VERSION ""

NS_ :

BS_:

BU_: IMU ECU IRTS_FL ACQUISINATOR TLM IRTS_FL TLM IRTS_FL TLM IRTS_FL TLM IRTS_FR TLM IRTS_FR ACQUISINATOR IRTS_FR IMU ACQUISINATOR IRTS_FR TLM IRTS_RL ACQUISINATOR IRTS_RL TLM IRTS_RL TLM TLM IRTS_RL ACQUISINATOR IRTS_RR ACQUISINATOR IRTS_RR TLM IRTS_RR IRTS_RR TLM TLM TLM ECU ECU ECU ACQUISINATOR

BO_ 0 ACQUISINATOR_JMP_TO_BLT: 1 Vector__XXX
 SG_ acquisinatore_id : 0|8@1+ (1,0) [0|255] "" Vector__XXX

BO_ 1 ACQUISINATOR_FLASH_TX: 0 Vector__XXX

BO_ 2 ACQUISINATOR_FLASH_RX: 0 Vector__XXX

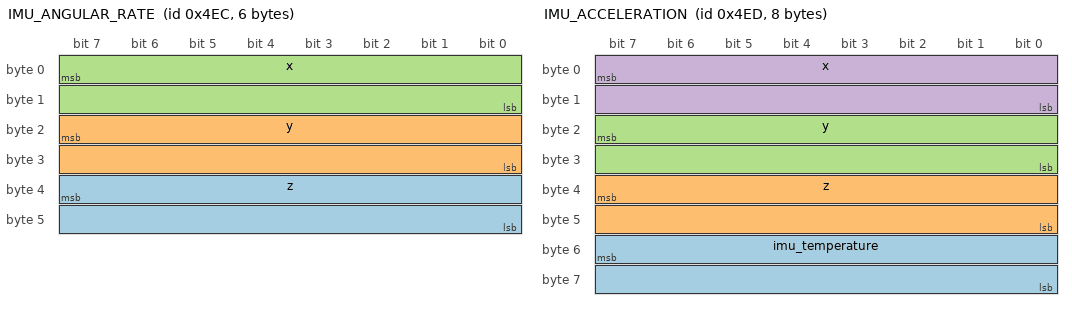
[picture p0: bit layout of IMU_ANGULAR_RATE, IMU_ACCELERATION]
BO_ 1260 IMU_ANGULAR_RATE: 6 Vector__XXX
 SG_ z : 39|16@0- (0.1,0) [0|245] "" Vector__XXX
 SG_ y : 23|16@0- (0.1,0) [0|245] "" Vector__XXX
 SG_ x : 7|16@0- (0.1,0) [0|245] "" Vector__XXX

BO_ 1261 IMU_ACCELERATION: 8 Vector__XXX
 SG_ imu_temperature : 55|16@0- (1,-32768) [-32768|32767] "" Vector__XXX
 SG_ z : 39|16@0- (0.01,0) [0|8] "" Vector__XXX
 SG_ y : 23|16@0- (0.01,0) [0|8] "" Vector__XXX
 SG_ x : 7|16@0- (0.01,0) [0|8] "" Vector__XXX

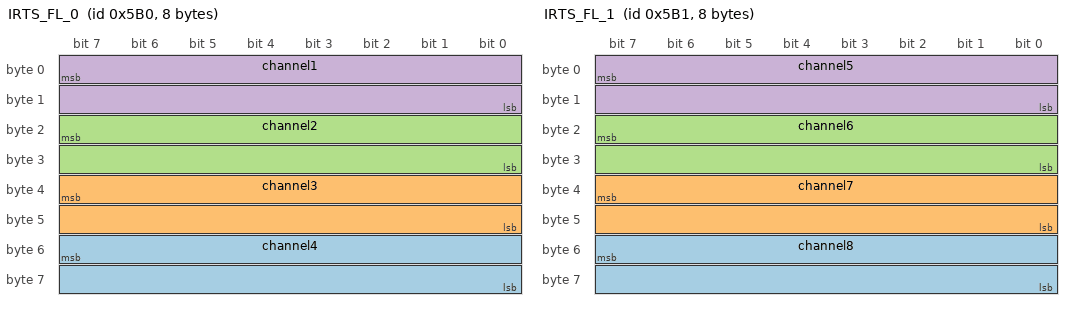
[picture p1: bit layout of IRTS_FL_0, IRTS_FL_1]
BO_ 1456 IRTS_FL_0: 8 Vector__XXX
 SG_ channel4 : 55|16@0+ (0.1,-100) [-100|0] "" Vector__XXX
 SG_ channel3 : 39|16@0+ (0.1,-100) [-100|0] "" Vector__XXX
 SG_ channel2 : 23|16@0+ (0.1,-100) [-100|0] "" Vector__XXX
 SG_ channel1 : 7|16@0+ (0.1,-100) [-100|0] "" Vector__XXX

BO_ 1457 IRTS_FL_1: 8 Vector__XXX
 SG_ channel8 : 55|16@0+ (0.1,-100) [-100|0] "" Vector__XXX
 SG_ channel7 : 39|16@0+ (0.1,-100) [-100|0] "" Vector__XXX
 SG_ channel6 : 23|16@0+ (0.1,-100) [-100|0] "" Vector__XXX
 SG_ channel5 : 7|16@0+ (0.1,-100) [-100|0] "" Vector__XXX

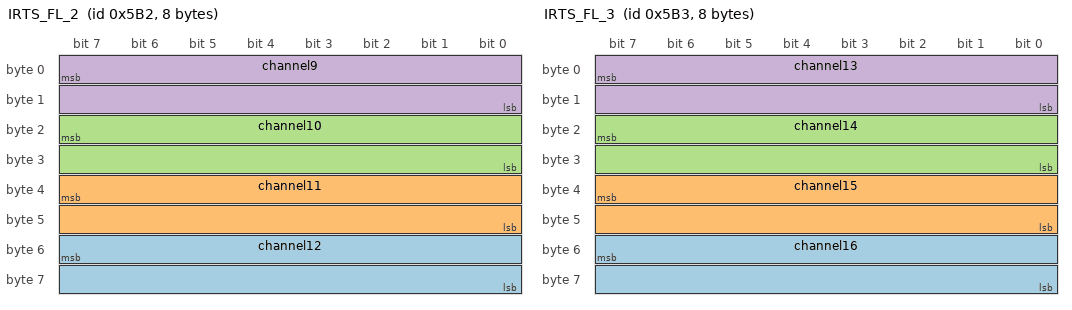
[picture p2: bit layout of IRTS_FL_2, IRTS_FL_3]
BO_ 1458 IRTS_FL_2: 8 Vector__XXX
 SG_ channel12 : 55|16@0+ (0.1,-100) [-100|0] "" Vector__XXX
 SG_ channel11 : 39|16@0+ (0.1,-100) [-100|0] "" Vector__XXX
 SG_ channel10 : 23|16@0+ (0.1,-100) [-100|0] "" Vector__XXX
 SG_ channel9 : 7|16@0+ (0.1,-100) [-100|0] "" Vector__XXX

BO_ 1459 IRTS_FL_3: 8 Vector__XXX
 SG_ channel16 : 55|16@0+ (0.1,-100) [-100|0] "" Vector__XXX
 SG_ channel15 : 39|16@0+ (0.1,-100) [-100|0] "" Vector__XXX
 SG_ channel14 : 23|16@0+ (0.1,-100) [-100|0] "" Vector__XXX
 SG_ channel13 : 7|16@0+ (0.1,-100) [-100|0] "" Vector__XXX

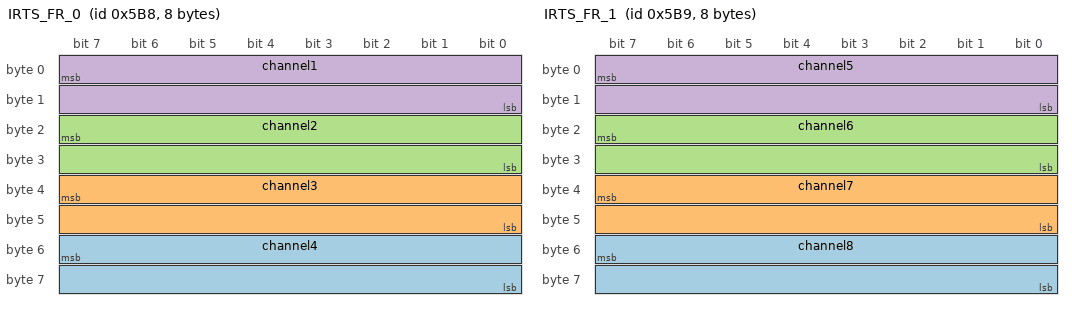
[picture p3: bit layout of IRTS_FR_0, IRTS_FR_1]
BO_ 1464 IRTS_FR_0: 8 Vector__XXX
 SG_ channel4 : 55|16@0+ (0.1,-100) [-100|0] "" Vector__XXX
 SG_ channel3 : 39|16@0+ (0.1,-100) [-100|0] "" Vector__XXX
 SG_ channel2 : 23|16@0+ (0.1,-100) [-100|0] "" Vector__XXX
 SG_ channel1 : 7|16@0+ (0.1,-100) [-100|0] "" Vector__XXX

BO_ 1465 IRTS_FR_1: 8 Vector__XXX
 SG_ channel8 : 55|16@0+ (0.1,-100) [-100|0] "" Vector__XXX
 SG_ channel7 : 39|16@0+ (0.1,-100) [-100|0] "" Vector__XXX
 SG_ channel6 : 23|16@0+ (0.1,-100) [-100|0] "" Vector__XXX
 SG_ channel5 : 7|16@0+ (0.1,-100) [-100|0] "" Vector__XXX

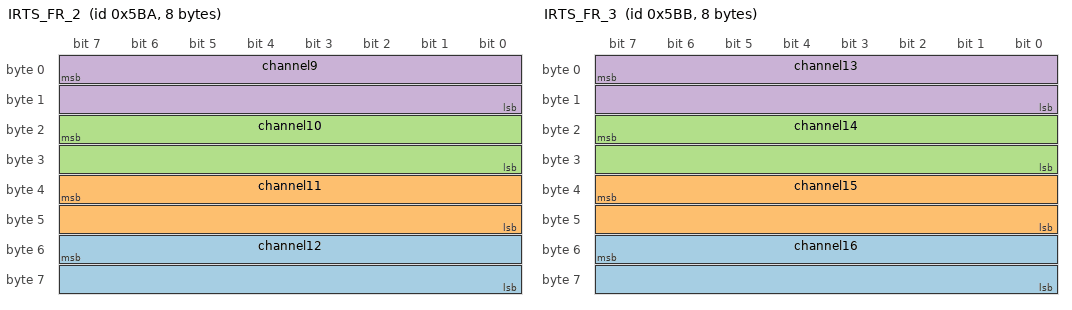
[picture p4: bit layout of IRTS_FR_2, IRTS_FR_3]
BO_ 1466 IRTS_FR_2: 8 Vector__XXX
 SG_ channel12 : 55|16@0+ (0.1,-100) [-100|0] "" Vector__XXX
 SG_ channel11 : 39|16@0+ (0.1,-100) [-100|0] "" Vector__XXX
 SG_ channel10 : 23|16@0+ (0.1,-100) [-100|0] "" Vector__XXX
 SG_ channel9 : 7|16@0+ (0.1,-100) [-100|0] "" Vector__XXX

BO_ 1467 IRTS_FR_3: 8 Vector__XXX
 SG_ channel16 : 55|16@0+ (0.1,-100) [-100|0] "" Vector__XXX
 SG_ channel15 : 39|16@0+ (0.1,-100) [-100|0] "" Vector__XXX
 SG_ channel14 : 23|16@0+ (0.1,-100) [-100|0] "" Vector__XXX
 SG_ channel13 : 7|16@0+ (0.1,-100) [-100|0] "" Vector__XXX

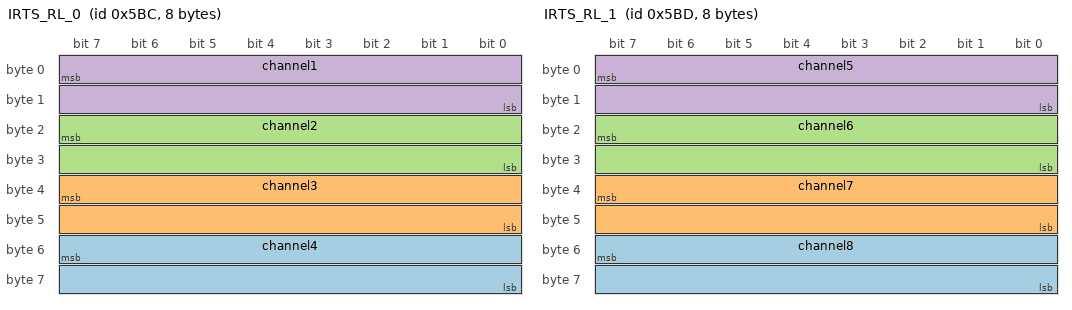
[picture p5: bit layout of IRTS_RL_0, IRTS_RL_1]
BO_ 1468 IRTS_RL_0: 8 Vector__XXX
 SG_ channel4 : 55|16@0+ (0.1,-100) [-100|0] "" Vector__XXX
 SG_ channel3 : 39|16@0+ (0.1,-100) [-100|0] "" Vector__XXX
 SG_ channel2 : 23|16@0+ (0.1,-100) [-100|0] "" Vector__XXX
 SG_ channel1 : 7|16@0+ (0.1,-100) [-100|0] "" Vector__XXX

BO_ 1469 IRTS_RL_1: 8 Vector__XXX
 SG_ channel8 : 55|16@0+ (0.1,-100) [-100|0] "" Vector__XXX
 SG_ channel7 : 39|16@0+ (0.1,-100) [-100|0] "" Vector__XXX
 SG_ channel6 : 23|16@0+ (0.1,-100) [-100|0] "" Vector__XXX
 SG_ channel5 : 7|16@0+ (0.1,-100) [-100|0] "" Vector__XXX

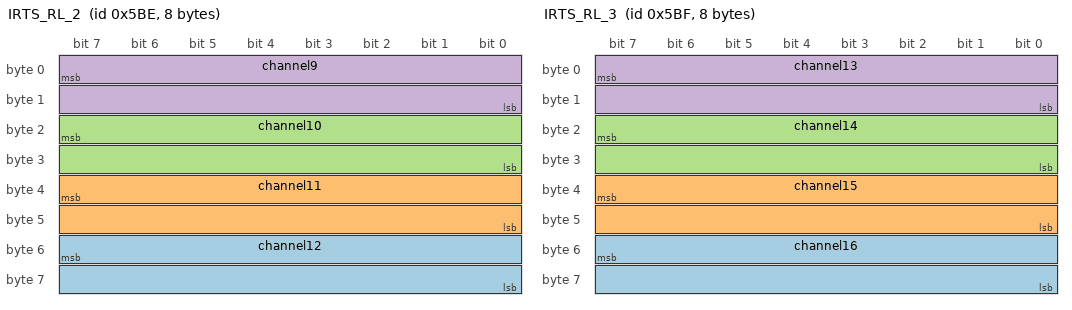
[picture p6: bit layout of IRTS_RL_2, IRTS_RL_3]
BO_ 1470 IRTS_RL_2: 8 Vector__XXX
 SG_ channel12 : 55|16@0+ (0.1,-100) [-100|0] "" Vector__XXX
 SG_ channel11 : 39|16@0+ (0.1,-100) [-100|0] "" Vector__XXX
 SG_ channel10 : 23|16@0+ (0.1,-100) [-100|0] "" Vector__XXX
 SG_ channel9 : 7|16@0+ (0.1,-100) [-100|0] "" Vector__XXX

BO_ 1471 IRTS_RL_3: 8 Vector__XXX
 SG_ channel16 : 55|16@0+ (0.1,-100) [-100|0] "" Vector__XXX
 SG_ channel15 : 39|16@0+ (0.1,-100) [-100|0] "" Vector__XXX
 SG_ channel14 : 23|16@0+ (0.1,-100) [-100|0] "" Vector__XXX
 SG_ channel13 : 7|16@0+ (0.1,-100) [-100|0] "" Vector__XXX

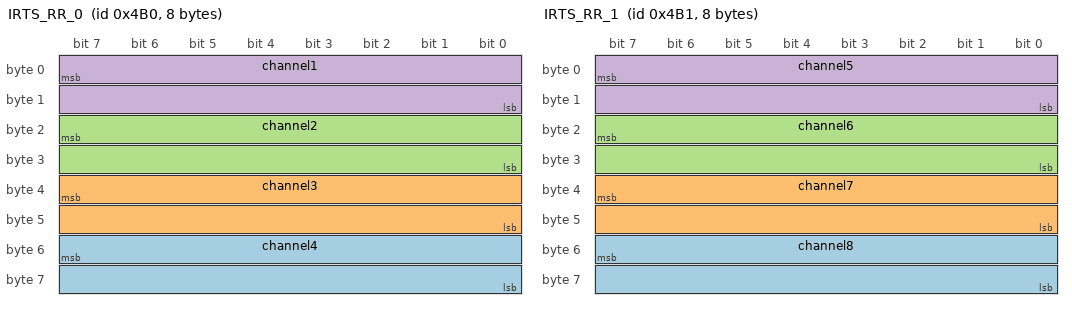
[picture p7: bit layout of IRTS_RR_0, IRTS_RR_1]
BO_ 1200 IRTS_RR_0: 8 Vector__XXX
 SG_ channel4 : 55|16@0+ (0.1,-100) [-100|0] "" Vector__XXX
 SG_ channel3 : 39|16@0+ (0.1,-100) [-100|0] "" Vector__XXX
 SG_ channel2 : 23|16@0+ (0.1,-100) [-100|0] "" Vector__XXX
 SG_ channel1 : 7|16@0+ (0.1,-100) [-100|0] "" Vector__XXX

BO_ 1201 IRTS_RR_1: 8 Vector__XXX
 SG_ channel8 : 55|16@0+ (0.1,-100) [-100|0] "" Vector__XXX
 SG_ channel7 : 39|16@0+ (0.1,-100) [-100|0] "" Vector__XXX
 SG_ channel6 : 23|16@0+ (0.1,-100) [-100|0] "" Vector__XXX
 SG_ channel5 : 7|16@0+ (0.1,-100) [-100|0] "" Vector__XXX

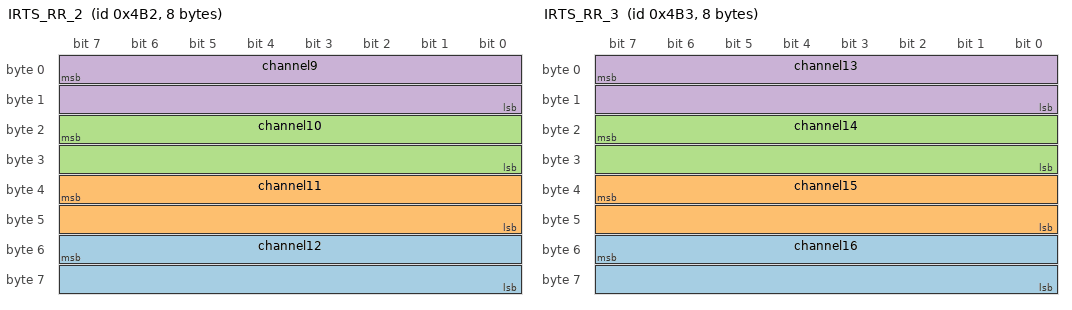
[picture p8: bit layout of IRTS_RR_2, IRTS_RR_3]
BO_ 1202 IRTS_RR_2: 8 Vector__XXX
 SG_ channel12 : 55|16@0+ (0.1,-100) [-100|0] "" Vector__XXX
 SG_ channel11 : 39|16@0+ (0.1,-100) [-100|0] "" Vector__XXX
 SG_ channel10 : 23|16@0+ (0.1,-100) [-100|0] "" Vector__XXX
 SG_ channel9 : 7|16@0+ (0.1,-100) [-100|0] "" Vector__XXX

BO_ 1203 IRTS_RR_3: 8 Vector__XXX
 SG_ channel16 : 55|16@0+ (0.1,-100) [-100|0] "" Vector__XXX
 SG_ channel15 : 39|16@0+ (0.1,-100) [-100|0] "" Vector__XXX
 SG_ channel14 : 23|16@0+ (0.1,-100) [-100|0] "" Vector__XXX
 SG_ channel13 : 7|16@0+ (0.1,-100) [-100|0] "" Vector__XXX

BO_ 1536 GPS_COORDS: 8 Vector__XXX
 SG_ longitude : 32|32@1+ (1,0) [0|4294967295] "" Vector__XXX
 SG_ latitude : 0|32@1+ (1,0) [0|4294967295] "" Vector__XXX

BO_ 1544 GPS_SPEED: 2 Vector__XXX
 SG_ speed : 0|16@1+ (1,0) [0|65535] "" Vector__XXX

BO_ 1552 ANGULAR_VELOCITY: 4 Vector__XXX
 SG_ fr : 16|16@1+ (0.006103608758678569,-200) [-200|200] "" Vector__XXX
 SG_ fl : 0|16@1+ (0.006103608758678569,-200) [-200|200] "" Vector__XXX

BO_ 1560 PEDAL_THROTTLE: 2 Vector__XXX
 SG_ throttle : 0|16@1+ (1.5259021896696422e-05,0) [0|1] "" Vector__XXX

BO_ 1568 PEDAL_BRAKES_PRESSURE: 4 Vector__XXX
 SG_ rear : 16|16@1+ (0.0015259021896696422,0) [0|100] "" Vector__XXX
 SG_ front : 0|16@1+ (0.0015259021896696422,0) [0|100] "" Vector__XXX

BO_ 1576 STEER_ANGLE: 4 Vector__XXX
 SG_ angle : 0|32@1+ (8.38190317349087e-08,-180) [-180|180] "" Vector__XXX

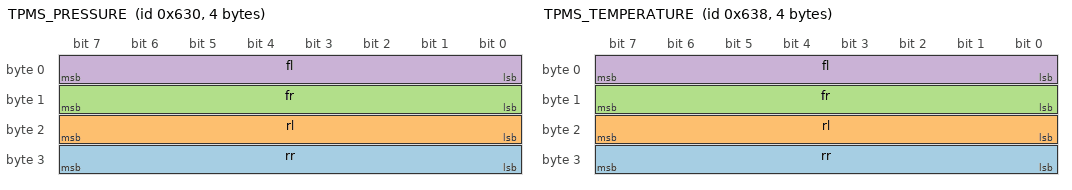
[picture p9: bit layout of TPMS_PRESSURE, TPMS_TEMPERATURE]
BO_ 1584 TPMS_PRESSURE: 4 Vector__XXX
 SG_ rr : 24|8@1+ (1.0,0) [0|255] "" Vector__XXX
 SG_ rl : 16|8@1+ (1.0,0) [0|255] "" Vector__XXX
 SG_ fr : 8|8@1+ (1.0,0) [0|255] "" Vector__XXX
 SG_ fl : 0|8@1+ (1.0,0) [0|255] "" Vector__XXX

BO_ 1592 TPMS_TEMPERATURE: 4 Vector__XXX
 SG_ rr : 24|8@1+ (1.0,0) [0|255] "" Vector__XXX
 SG_ rl : 16|8@1+ (1.0,0) [0|255] "" Vector__XXX
 SG_ fr : 8|8@1+ (1.0,0) [0|255] "" Vector__XXX
 SG_ fl : 0|8@1+ (1.0,0) [0|255] "" Vector__XXX

BO_ 1600 TLM_UNIX_TIMESTAMP: 8 Vector__XXX
 SG_ timestamp : 0|64@1+ (1,0) [0|18446744073709551615] "" Vector__XXX

BO_ 1608 TLM_LAP_TIME: 4 Vector__XXX
 SG_ lap_time : 16|16@1+ (0.015259021896696421,0) [0|1000] "" Vector__XXX
 SG_ lap_count : 0|16@1+ (1,0) [0|65535] "" Vector__XXX

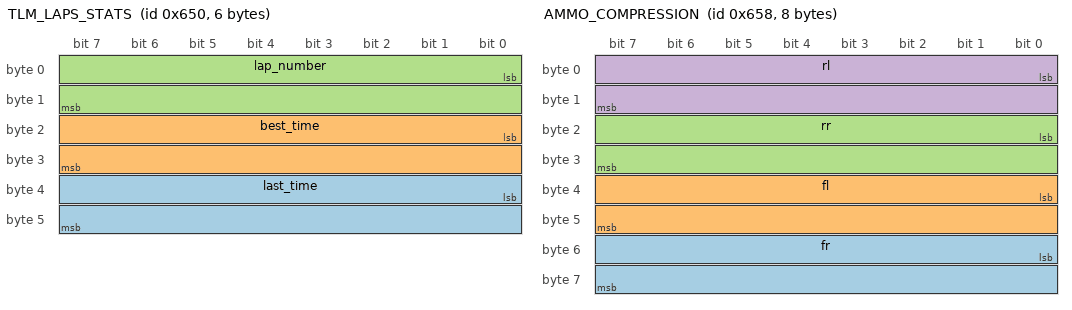
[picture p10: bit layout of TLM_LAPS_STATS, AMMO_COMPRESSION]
BO_ 1616 TLM_LAPS_STATS: 6 Vector__XXX
 SG_ last_time : 32|16@1+ (0.015259021896696421,0) [0|1000] "" Vector__XXX
 SG_ best_time : 16|16@1+ (0.015259021896696421,0) [0|1000] "" Vector__XXX
 SG_ lap_number : 0|16@1+ (1,0) [0|65535] "" Vector__XXX

BO_ 1624 AMMO_COMPRESSION: 8 Vector__XXX
 SG_ fr : 48|16@1+ (0.0010681315327687496,-20) [-20|50] "" Vector__XXX
 SG_ fl : 32|16@1+ (0.0010681315327687496,-20) [-20|50] "" Vector__XXX
 SG_ rr : 16|16@1+ (0.0010681315327687496,-50) [-50|20] "" Vector__XXX
 SG_ rl : 0|16@1+ (0.0010681315327687496,-50) [-50|20] "" Vector__XXX

BO_ 1632 LINK_DEFORMATION: 5 Vector__XXX
 SG_ deformation : 8|32@1+ (1.3969838622484784e-09,-3.0) [-3.0|3.0] "" Vector__XXX
 SG_ rod_id : 0|8@1+ (1,0) [0|255] "" Vector__XXX

BO_ 8 LINK_DEFORMATION_SET_CALIBRATION: 5 Vector__XXX
 SG_ deformation : 8|32@1+ (1.3969838622484784e-09,-3.0) [-3.0|3.0] "" Vector__XXX
 SG_ rod_id : 0|8@1+ (1,0) [0|255] "" Vector__XXX

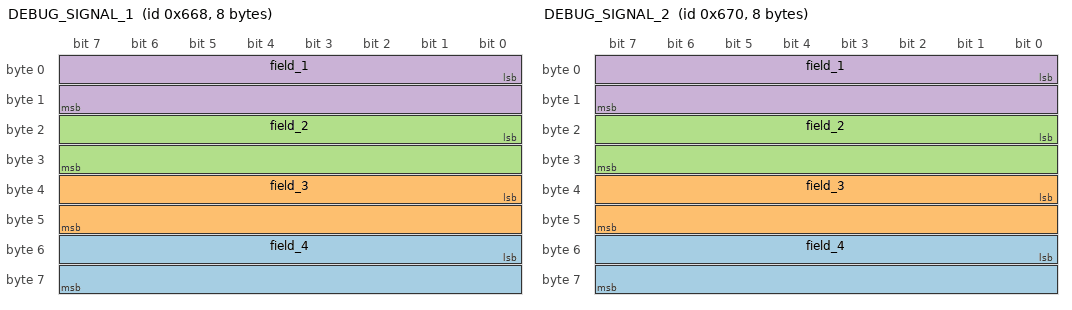
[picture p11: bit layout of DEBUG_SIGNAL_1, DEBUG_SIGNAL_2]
BO_ 1640 DEBUG_SIGNAL_1: 8 Vector__XXX
 SG_ field_4 : 48|16@1+ (3.0518043793392844e-05,-1) [-1|1] "" Vector__XXX
 SG_ field_3 : 32|16@1+ (3.0518043793392844e-05,-1) [-1|1] "" Vector__XXX
 SG_ field_2 : 16|16@1+ (3.0518043793392844e-05,-1) [-1|1] "" Vector__XXX
 SG_ field_1 : 0|16@1+ (3.0518043793392844e-05,-1) [-1|1] "" Vector__XXX

BO_ 1648 DEBUG_SIGNAL_2: 8 Vector__XXX
 SG_ field_4 : 48|16@1+ (3.0518043793392844e-05,-1) [-1|1] "" Vector__XXX
 SG_ field_3 : 32|16@1+ (3.0518043793392844e-05,-1) [-1|1] "" Vector__XXX
 SG_ field_2 : 16|16@1+ (3.0518043793392844e-05,-1) [-1|1] "" Vector__XXX
 SG_ field_1 : 0|16@1+ (3.0518043793392844e-05,-1) [-1|1] "" Vector__XXX

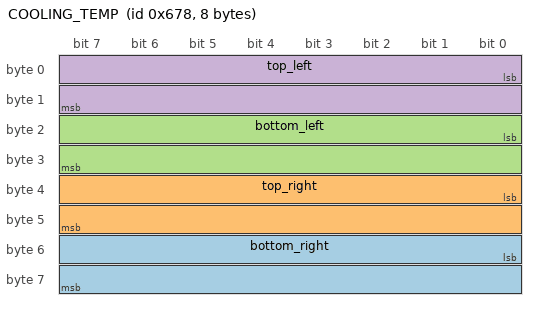
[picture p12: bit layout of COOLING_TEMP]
BO_ 1656 COOLING_TEMP: 8 Vector__XXX
 SG_ bottom_right : 48|16@1+ (0.0018310826276035706,-10) [-10|110] "" Vector__XXX
 SG_ top_right : 32|16@1+ (0.0018310826276035706,-10) [-10|110] "" Vector__XXX
 SG_ bottom_left : 16|16@1+ (0.0018310826276035706,-10) [-10|110] "" Vector__XXX
 SG_ top_left : 0|16@1+ (0.0018310826276035706,-10) [-10|110] "" Vector__XXX

CM_ BO_ 1260 "Inertial Measurement Unit [x,y,z]-axis angular rate value. 0.01dps per bit, Big-Endian, 16bit Total, signed";
CM_ BO_ 1261 "Inertial Measurement Unit [x,y,z]-axis acceleration value. 0.01g per bit, Big-Endian, 16bit Total, signed";
CM_ BO_ 1456 "Front Left wheel InfraRed Temperature Sensor data, channels 1 through 4. 0.1˚C per bit, -100˚C offset, Big-Endian, 16bit Total, unsigned.";
CM_ BO_ 1457 "Front Left wheel InfraRed Temperature Sensor data, channels 5 through 8. 0.1˚C per bit, -100˚C offset, Big-Endian, 16bit Total, unsigned.";
CM_ BO_ 1458 "Front Left wheel InfraRed Temperature Sensor data, channels 9 through 12. 0.1˚C per bit, -100˚C offset, Big-Endian, 16bit Total, unsigned.";
CM_ BO_ 1459 "Front Left wheel InfraRed Temperature Sensor data, channels 13 through 16. 0.1˚C per bit, -100˚C offset, Big-Endian, 16bit Total, unsigned.";
CM_ BO_ 1464 "Front Right wheel InfraRed Temperature Sensor data, channels 1 through 4. 0.1˚C per bit, -100˚C offset, Big-Endian, 16bit Total, unsigned.";
CM_ BO_ 1465 "Front Right wheel InfraRed Temperature Sensor data, channels 5 through 8. 0.1˚C per bit, -100˚C offset, Big-Endian, 16bit Total, unsigned.";
CM_ BO_ 1466 "Front Right wheel InfraRed Temperature Sensor data, channels 9 through 12. 0.1˚C per bit, -100˚C offset, Big-Endian, 16bit Total, unsigned.";
CM_ BO_ 1467 "Front Right wheel InfraRed Temperature Sensor data, channels 13 through 16. 0.1˚C per bit, -100˚C offset, Big-Endian, 16bit Total, unsigned.";
CM_ BO_ 1468 "Rear Left wheel InfraRed Temperature Sensor data, channels 1 through 4. 0.1˚C per bit, -100˚C offset, Big-Endian, 16bit Total, unsigned.";
CM_ BO_ 1469 "Rear Left wheel InfraRed Temperature Sensor data, channels 5 through 8. 0.1˚C per bit, -100˚C offset, Big-Endian, 16bit Total, unsigned.";
CM_ BO_ 1470 "Rear Left wheel InfraRed Temperature Sensor data, channels 9 through 12. 0.1˚C per bit, -100˚C offset, Big-Endian, 16bit Total, unsigned.";
CM_ BO_ 1471 "Rear Left wheel InfraRed Temperature Sensor data, channels 13 through 16. 0.1˚C per bit, -100˚C offset, Big-Endian, 16bit Total, unsigned.";
CM_ BO_ 1200 "Rear Right wheel InfraRed Temperature Sensor data, channels 1 through 4. 0.1˚C per bit, -100˚C offset, Big-Endian, 16bit Total, unsigned.";
CM_ BO_ 1201 "Rear Right wheel InfraRed Temperature Sensor data, channels 5 through 8. 0.1˚C per bit, -100˚C offset, Big-Endian, 16bit Total, unsigned.";
CM_ BO_ 1202 "Rear Right wheel InfraRed Temperature Sensor data, channels 9 through 12. 0.1˚C per bit, -100˚C offset, Big-Endian, 16bit Total, unsigned.";
CM_ BO_ 1203 "Rear Right wheel InfraRed Temperature Sensor data, channels 13 through 16. 0.1˚C per bit, -100˚C offset, Big-Endian, 16bit Total, unsigned.";
CM_ BO_ 1536 "Coordinates received from GPS";
CM_ BO_ 1544 "Speed received from GPS";
CM_ BO_ 1552 "Encoder and inverter speed in rad/sec";
CM_ BO_ 1560 "Pedal Throttle , already calibrated";
CM_ BO_ 1568 "Pedal brakes pressures in bar, already calibrated";
CM_ BO_ 1576 "Steering angle in degrees";
CM_ BO_ 1584 "Tire Pressure Monitoring System, pressure of each tire";
CM_ BO_ 1592 "Tire Pressure Monitoring System, temperature of each tire";
CM_ BO_ 1624 "Position of the ammos";
CM_ BO_ 1632 "Message for the arm deformation";
CM_ BO_ 8 "Calibration command for link deformation";
CM_ BO_ 1640 "Debug signals";
CM_ BO_ 1648 "Debug signals";
CM_ BO_ 1656 "Cooling temperature";
BA_DEF_ BO_  "GenMsgCycleTime" INT 0 65535;
BA_DEF_DEF_  "GenMsgCycleTime" 0;
BA_ "GenMsgCycleTime" BO_ 1552 10;
BA_ "GenMsgCycleTime" BO_ 1560 10;
BA_ "GenMsgCycleTime" BO_ 1568 10;
BA_ "GenMsgCycleTime" BO_ 1576 10;
BA_ "GenMsgCycleTime" BO_ 1600 1000;
BA_ "GenMsgCycleTime" BO_ 1616 1000;
BA_ "GenMsgCycleTime" BO_ 1624 10;
BA_ "GenMsgCycleTime" BO_ 1632 10;
BA_ "GenMsgCycleTime" BO_ 1640 10;
BA_ "GenMsgCycleTime" BO_ 1648 10;
BA_ "GenMsgCycleTime" BO_ 1656 500;
